AUTOSAR XML (schema 00046)
package /SWComponent
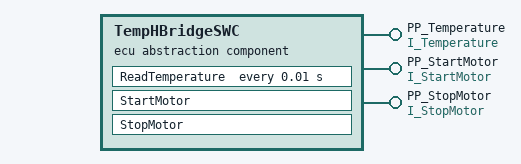
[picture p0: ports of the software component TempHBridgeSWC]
  ecu abstraction sw component type TempHBridgeSWC
    provide port PP_Temperature: provided-interface=I_Temperature
    provide port PP_StartMotor: provided-interface=I_StartMotor
    provide port PP_StopMotor: provided-interface=I_StopMotor
    behavior IB_SWC
      timing event TE_10ms: start-on-event=ReadTemperature, period=0.01
      operation invoked event OIE_StartMotor: start-on-event=StartMotor, operation=PP_StartMotor.StartMotor
      operation invoked event OIE_StopMotor: start-on-event=StopMotor, operation=PP_StopMotor.StoptMotor
      runnable ReadTemperature: symbol=Function_ReadTemperature
        data-send-points:
          access VA_Temp: accessed-variable=PP_Temperature.Temperature
      runnable StartMotor: symbol=Function_StartMotor
      runnable StopMotor: symbol=Function_StopMotor
